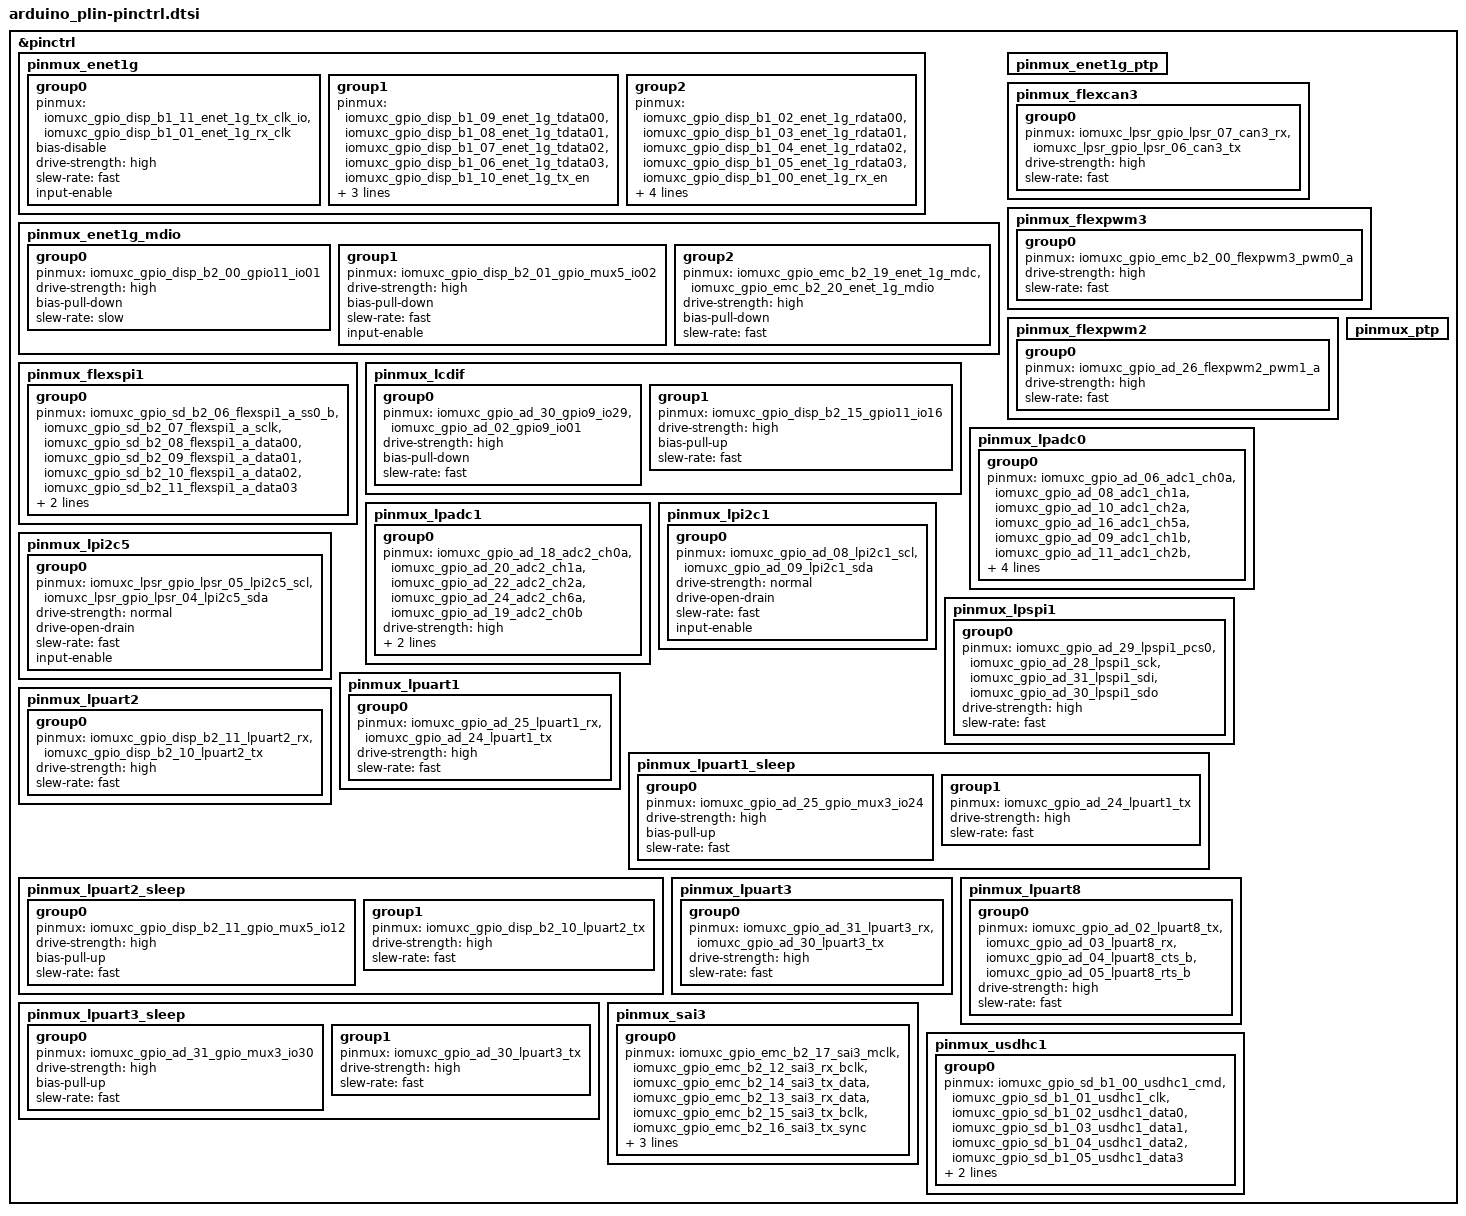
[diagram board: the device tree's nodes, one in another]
/*
 * Copyright (c) 2022, NXP
 * SPDX-License-Identifier: Apache-2.0
 *
 * Note: File generated by rt_cfg_utils.py
 * from mimxrt1170_evk.mex
 */

#include <nxp/nxp_imx/rt/mimxrt1176dvmaa-pinctrl.dtsi>

&pinctrl {

	pinmux_enet1g: pinmux_enet1g {
		group0 {
			pinmux = <&iomuxc_gpio_disp_b1_11_enet_1g_tx_clk_io>,	// ENET_RGMII_TXC
				<&iomuxc_gpio_disp_b1_01_enet_1g_rx_clk>;	// ENET_RGMII_RXC
			bias-disable;
			drive-strength = "high";
			slew-rate = "fast";
			input-enable;
		};
		group1 {
			pinmux = <&iomuxc_gpio_disp_b1_09_enet_1g_tdata00>,	// ENET_RGMII_TXD0
				<&iomuxc_gpio_disp_b1_08_enet_1g_tdata01>,	// ENET_RGMII_TXD1
				<&iomuxc_gpio_disp_b1_07_enet_1g_tdata02>,	// ENET_RGMII_TXD2
				<&iomuxc_gpio_disp_b1_06_enet_1g_tdata03>,	// ENET_RGMII_TXD3
				<&iomuxc_gpio_disp_b1_10_enet_1g_tx_en>;	// ENET_RGMII_TX_EN
			drive-strength = "high";
			bias-pull-up;
			slew-rate = "fast";
		};
		group2 {
			pinmux = <&iomuxc_gpio_disp_b1_02_enet_1g_rdata00>,	// ENET_RGMII_RXD0
				<&iomuxc_gpio_disp_b1_03_enet_1g_rdata01>,	// ENET_RGMII_RXD1
				<&iomuxc_gpio_disp_b1_04_enet_1g_rdata02>,	// ENET_RGMII_RXD2
				<&iomuxc_gpio_disp_b1_05_enet_1g_rdata03>,	// ENET_RGMII_RXD3
				<&iomuxc_gpio_disp_b1_00_enet_1g_rx_en>;	// ENET_RGMII_RX_EN
			drive-strength = "high";
			bias-pull-down;
			slew-rate = "fast";
			input-enable;
		};
	};

	pinmux_enet1g_mdio: pinmux_enet1g_mdio {
		group0 {
			pinmux = <&iomuxc_gpio_disp_b2_00_gpio11_io01>;	// ETHPHY_RST_B
			drive-strength = "high";
			bias-pull-down;
			slew-rate = "slow";
		};
		group1 {
			pinmux = <&iomuxc_gpio_disp_b2_01_gpio_mux5_io02>;	// RGMII1_PHY_INTB
			drive-strength = "high";
			bias-pull-down;
			slew-rate = "fast";
			input-enable;
		};
		group2 {
			pinmux = <&iomuxc_gpio_emc_b2_19_enet_1g_mdc>,	// ENET_RGMII_MDC
				<&iomuxc_gpio_emc_b2_20_enet_1g_mdio>;		// ENET_RGMII_MDIO
			drive-strength = "high";
			bias-pull-down;
			slew-rate = "fast";
		};
	};

	pinmux_enet1g_ptp: pinmux_enet1g_ptp {
	};

	pinmux_flexcan3: pinmux_flexcan3 {
		group0 {
			pinmux = <&iomuxc_lpsr_gpio_lpsr_07_can3_rx>,
				<&iomuxc_lpsr_gpio_lpsr_06_can3_tx>;
			drive-strength = "high";
			slew-rate = "fast";
		};
	};

	pinmux_flexpwm3: pinmux_flexpwm3 {
		group0 {
			pinmux = <&iomuxc_gpio_emc_b2_03_flexpwm3_pwm1_b>;
			pinmux = <&iomuxc_gpio_emc_b2_02_flexpwm3_pwm1_a>;
			pinmux = <&iomuxc_gpio_emc_b2_01_flexpwm3_pwm0_b>;
			pinmux = <&iomuxc_gpio_emc_b2_00_flexpwm3_pwm0_a>;
			drive-strength = "high";
			slew-rate = "fast";
		};
	};

	pinmux_flexpwm2: pinmux_flexpwm2 {
		group0 {
			pinmux = <&iomuxc_gpio_ad_29_flexpwm2_pwm2_b>;
			pinmux = <&iomuxc_gpio_ad_28_flexpwm2_pwm2_a>;
			pinmux = <&iomuxc_gpio_ad_27_flexpwm2_pwm1_b>;
			pinmux = <&iomuxc_gpio_ad_26_flexpwm2_pwm1_a>;
			drive-strength = "high";
			slew-rate = "fast";
		};
	};

	pinmux_flexspi1: pinmux_flexspi1 {
		group0 {
			pinmux = <&iomuxc_gpio_sd_b2_06_flexspi1_a_ss0_b>,
				<&iomuxc_gpio_sd_b2_07_flexspi1_a_sclk>,
				<&iomuxc_gpio_sd_b2_08_flexspi1_a_data00>,
				<&iomuxc_gpio_sd_b2_09_flexspi1_a_data01>,
				<&iomuxc_gpio_sd_b2_10_flexspi1_a_data02>,
				<&iomuxc_gpio_sd_b2_11_flexspi1_a_data03>;
			bias-pull-down;
			input-enable;
		};
	};

	pinmux_lcdif: pinmux_lcdif {
		group0 {
			pinmux = <&iomuxc_gpio_ad_30_gpio9_io29>,
				<&iomuxc_gpio_ad_02_gpio9_io01>;
			drive-strength = "high";
			bias-pull-down;
			slew-rate = "fast";
		};
		group1 {
			pinmux = <&iomuxc_gpio_disp_b2_15_gpio11_io16>;
			drive-strength = "high";
			bias-pull-up;
			slew-rate = "fast";
		};
	};

	pinmux_lpadc0: pinmux_lpadc0 {
		group0 {
			pinmux = <&iomuxc_gpio_ad_06_adc1_ch0a>,
				<&iomuxc_gpio_ad_08_adc1_ch1a>,
				<&iomuxc_gpio_ad_10_adc1_ch2a>,
				<&iomuxc_gpio_ad_16_adc1_ch5a>,
				<&iomuxc_gpio_ad_09_adc1_ch1b>,
				<&iomuxc_gpio_ad_11_adc1_ch2b>,
				<&iomuxc_gpio_ad_17_adc1_ch5b>;
			drive-strength = "high";
			bias-pull-down;
			slew-rate = "fast";
		};
	};

	pinmux_lpadc1: pinmux_lpadc1 {
		group0 {
			pinmux = <&iomuxc_gpio_ad_18_adc2_ch0a>,
				<&iomuxc_gpio_ad_20_adc2_ch1a>,
				<&iomuxc_gpio_ad_22_adc2_ch2a>,
				<&iomuxc_gpio_ad_24_adc2_ch6a>,
				<&iomuxc_gpio_ad_19_adc2_ch0b>;
			drive-strength = "high";
			bias-pull-down;
			slew-rate = "fast";
		};
	};

	pinmux_lpi2c1: pinmux_lpi2c1 {
		group0 {
			pinmux = <&iomuxc_gpio_ad_08_lpi2c1_scl>,
				<&iomuxc_gpio_ad_09_lpi2c1_sda>;
			drive-strength = "normal";
			drive-open-drain;
			slew-rate = "fast";
			input-enable;
		};
	};

	pinmux_lpi2c5: pinmux_lpi2c5 {
		group0 {
			pinmux = <&iomuxc_lpsr_gpio_lpsr_05_lpi2c5_scl>,
				<&iomuxc_lpsr_gpio_lpsr_04_lpi2c5_sda>;
			drive-strength = "normal";
			drive-open-drain;
			slew-rate = "fast";
			input-enable;
		};
	};

	pinmux_lpspi1: pinmux_lpspi1 {
		group0 {
			pinmux = <&iomuxc_gpio_ad_29_lpspi1_pcs0>,
				<&iomuxc_gpio_ad_28_lpspi1_sck>,
				<&iomuxc_gpio_ad_31_lpspi1_sdi>,
				<&iomuxc_gpio_ad_30_lpspi1_sdo>;
			drive-strength = "high";
			slew-rate = "fast";
		};
	};

	pinmux_lpuart1: pinmux_lpuart1 {
		group0 {
			pinmux = <&iomuxc_gpio_ad_25_lpuart1_rx>,
				<&iomuxc_gpio_ad_24_lpuart1_tx>;
			drive-strength = "high";
			slew-rate = "fast";
		};
	};

	pinmux_lpuart1_sleep: pinmux_lpuart1_sleep {
		group0 {
			pinmux = <&iomuxc_gpio_ad_25_gpio_mux3_io24>;
			drive-strength = "high";
			bias-pull-up;
			slew-rate = "fast";
		};
		group1 {
			pinmux = <&iomuxc_gpio_ad_24_lpuart1_tx>;
			drive-strength = "high";
			slew-rate = "fast";
		};
	};

	pinmux_lpuart2: pinmux_lpuart2 {
		group0 {
			pinmux = <&iomuxc_gpio_disp_b2_11_lpuart2_rx>,
				<&iomuxc_gpio_disp_b2_10_lpuart2_tx>;
			drive-strength = "high";
			slew-rate = "fast";
		};
	};

	pinmux_lpuart2_sleep: pinmux_lpuart2_sleep {
		group0 {
			pinmux = <&iomuxc_gpio_disp_b2_11_gpio_mux5_io12>;
			drive-strength = "high";
			bias-pull-up;
			slew-rate = "fast";
		};
		group1 {
			pinmux = <&iomuxc_gpio_disp_b2_10_lpuart2_tx>;
			drive-strength = "high";
			slew-rate = "fast";
		};
	};

	pinmux_lpuart3: pinmux_lpuart3 {
		group0 {
			pinmux = <&iomuxc_gpio_ad_31_lpuart3_rx>,
				<&iomuxc_gpio_ad_30_lpuart3_tx>;
			drive-strength = "high";
			slew-rate = "fast";
		};
	};

	pinmux_lpuart3_sleep: pinmux_lpuart3_sleep {
		group0 {
			pinmux = <&iomuxc_gpio_ad_31_gpio_mux3_io30>;
			drive-strength = "high";
			bias-pull-up;
			slew-rate = "fast";
		};
		group1 {
			pinmux = <&iomuxc_gpio_ad_30_lpuart3_tx>;
			drive-strength = "high";
			slew-rate = "fast";
		};
	};

	pinmux_lpuart8: pinmux_lpuart8 {
		group0 {
			pinmux = <&iomuxc_gpio_ad_02_lpuart8_tx>,
				<&iomuxc_gpio_ad_03_lpuart8_rx>,
				<&iomuxc_gpio_ad_04_lpuart8_cts_b>,
				<&iomuxc_gpio_ad_05_lpuart8_rts_b>;
			drive-strength = "high";
			slew-rate = "fast";
		};
	};

	/* intentionally left empty */
	pinmux_ptp: pinmux_ptp {
	};

	pinmux_sai3: pinmux_sai3 {
		group0 {
			pinmux = <&iomuxc_gpio_emc_b2_17_sai3_mclk>,
				<&iomuxc_gpio_emc_b2_12_sai3_rx_bclk>,
				<&iomuxc_gpio_emc_b2_14_sai3_tx_data>,
				<&iomuxc_gpio_emc_b2_13_sai3_rx_data>,
				<&iomuxc_gpio_emc_b2_15_sai3_tx_bclk>,
				<&iomuxc_gpio_emc_b2_16_sai3_tx_sync>;
			drive-strength = "high";
			slew-rate = "fast";
			input-enable;
		};
	};

	pinmux_usdhc1: pinmux_usdhc1 {
		group0 {
			pinmux = <&iomuxc_gpio_sd_b1_00_usdhc1_cmd>,
				<&iomuxc_gpio_sd_b1_01_usdhc1_clk>,
				<&iomuxc_gpio_sd_b1_02_usdhc1_data0>,
				<&iomuxc_gpio_sd_b1_03_usdhc1_data1>,
				<&iomuxc_gpio_sd_b1_04_usdhc1_data2>,
				<&iomuxc_gpio_sd_b1_05_usdhc1_data3>;
			bias-pull-up;
			input-enable;
		};
	};
};

